# haltium_isimcore register map
Vendor: Nordic Semiconductor; Series: nRFHaltium; File version: 1
CPU: CM33 r0p4, little endian, MPU, FPU, 3 interrupt priority bits, 480 interrupts
Registers are 32-bit, read-write, reset 0x0 unless marked. A register's access mark holds for its fields unless they carry their own. Offsets are from the block's base; [hi:lo] are bit positions; lines under a group give offsets from that group; {n}, {i} and the like mark numbered series.

## GLOBAL_GGENERIC59_NS — GENERIC 0
Base 0xBF001000
Same registers: GENERIC0_NS 0x47002000, GENERIC6_NS 0x47021000, GENERIC7_NS 0x47022000, GENERIC8_NS 0x47023000, GENERIC9_NS 0x47024000, GLOBAL_GGENERIC55_NS 0x4F8D3000, GLOBAL_GGENERIC56_NS 0x4F8D4000, GLOBAL_GGENERIC57_NS 0x4F8D5000, GLOBAL_GGENERIC58_NS 0x4F8D6000, GENERIC2_NS 0x57004000, GENERIC4_NS 0x57014000, GENERIC5_NS 0x57015000, GLOBAL_GGENERIC55_S 0x5F8D3000, GLOBAL_GGENERIC56_S 0x5F8D4000, GLOBAL_GGENERIC57_S 0x5F8D5000, GLOBAL_GGENERIC58_S 0x5F8D6000, GLOBAL_GGENERIC59_S 0xBF001000 (alternate view of GLOBAL_GGENERIC59_NS), GLOBAL_GGENERIC60_NS 0xBF003000, GLOBAL_GGENERIC60_S 0xBF003000 (alternate view of GLOBAL_GGENERIC60_NS), GLOBAL_TSGEN_NS 0xBF041000, GLOBAL_ETB_NS 0xBF044000, GLOBAL_ETR_NS 0xBF045000
0x00 TASKS_GENERICTASK wo — Generic event
  [0] TASKS_GENERICTASK
    1=Trigger task
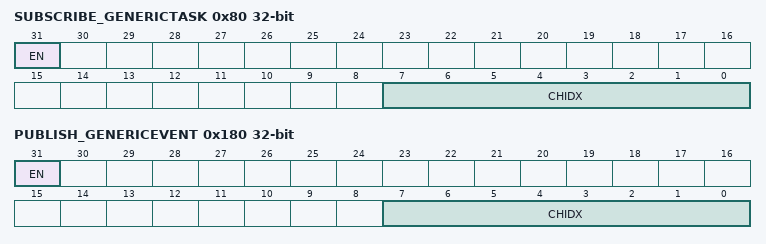
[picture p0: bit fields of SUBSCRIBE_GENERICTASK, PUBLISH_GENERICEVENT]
0x80 SUBSCRIBE_GENERICTASK — Subscribe configuration for task GENERICTASK
  [31] EN
    0=Disabled (Disable subscription); 1=Enabled (Enable subscription)
  [7:0] CHIDX — DPPI channel that task GENERICTASK will subscribe to
0x100 EVENTS_GENERICEVENT — Generic event
  [0] EVENTS_GENERICEVENT
    0=NotGenerated (Event not generated); 1=Generated (Event generated)
0x180 PUBLISH_GENERICEVENT — Publish configuration for event GENERICEVENT
  [31] EN
    0=Disabled (Disable publishing); 1=Enabled (Enable publishing)
  [7:0] CHIDX — DPPI channel that event GENERICEVENT will publish to
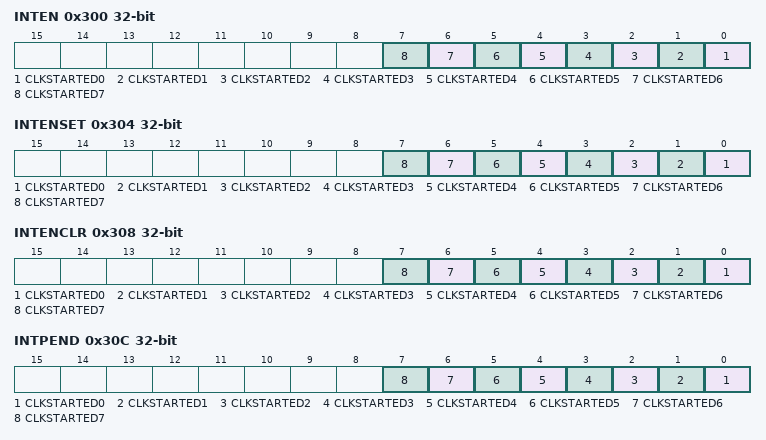
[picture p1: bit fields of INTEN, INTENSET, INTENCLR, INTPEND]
0x300 INTEN — Enable or disable interrupt
  [0] GENERICEVENT — Enable or disable interrupt for event GENERICEVENT
    0=Disabled; 1=Enabled
0x304 INTENSET — Enable interrupt
  [0] GENERICEVENT — Write '1' to enable interrupt for event GENERICEVENT
    on read: 0=Disabled (Read: Disabled); 1=Enabled (Read: Enabled) | on write: 1=Set (Enable)
0x308 INTENCLR — Disable interrupt
  [0] GENERICEVENT — Write '1' to disable interrupt for event GENERICEVENT
    on read: 0=Disabled (Read: Disabled); 1=Enabled (Read: Enabled) | on write: 1=Clear (Disable)

## CPUCONF_NS — CPU Configuration 0
Base 0x47001000
Same registers: CPUCONF_S 0x57001000
0x00 TASKS_ERASECACHE wo — Erase the caches used by the CPU.
  [0] TASKS_ERASECACHE
    1=Trigger task
0x500 INITSVTOR — Initial value of the secure VTOR (Vector Table Offset Register) after CPU reset.
  [31:0] INITSVTOR — Initial value of the VTOR.
0x504 INITNSVTOR — Initial value of the non-secure VTOR (Vector Table Offset Register).
  [31:0] INITNSVTOR — Initial value of the VTOR.
0x508 CPUSTART — Enable for starting the CPU
  [0] EN — Enable to start the CPU.
    0=Stopped (CPU stopped.); 1=Started (CPU started.)
0x50C CPUWAIT — Enable for the CPU wait.
  [0] EN — Enable to the CPU wait.
    0=Disabled (CPU is not waiting.); 1=Enabled (CPU is waiting.)

## LRC0_NS — LRC 0
Base 0x57003000
Same registers: LRC1_NS 0x57013000
{0x0+4i} TASKS_CLKSTART[{i}] (i=0..7) wo — Description collection: Start the clock source [n]
  [0] TASKS_CLKSTART — Start the clock source [n]
    1=Trigger task
{0x20+4i} TASKS_CLKSTOP[{i}] (i=0..7) wo — Description collection: Clear the TASKS_CLKSTART[n] request
  [0] TASKS_CLKSTOP — Clear the TASKS_CLKSTART[n] request
    1=Trigger task
0x40 TASKS_CONSTLAT wo — Enable constant latency mode
  [0] TASKS_CONSTLAT
    1=Trigger task
0x44 TASKS_LOWPWR wo — Enable Low Power mode
  [0] TASKS_LOWPWR
    1=Trigger task
{0x100+4i} EVENTS_CLKSTARTED[{i}] (i=0..7) — Description collection: Clock [n] started
  [0] EVENTS_CLKSTARTED — Clock [n] started
    0=NotGenerated (Event not generated); 1=Generated (Event generated)
0x300 INTEN — Enable or disable interrupt
  [all] fields
    0=Disabled; 1=Enabled
  [n] CLKSTARTED{n} (n=0..7) — Enable or disable interrupt for event CLKSTARTED[{n}]
0x304 INTENSET — Enable interrupt
  [all] fields
    on read: 0=Disabled (Read: Disabled); 1=Enabled (Read: Enabled) | on write: 1=Set (Enable)
  [n] CLKSTARTED{n} (n=0..7) — Write '1' to enable interrupt for event CLKSTARTED[{n}]
0x308 INTENCLR — Disable interrupt
  [all] fields
    on read: 0=Disabled (Read: Disabled); 1=Enabled (Read: Enabled) | on write: 1=Clear (Disable)
  [n] CLKSTARTED{n} (n=0..7) — Write '1' to disable interrupt for event CLKSTARTED[{n}]
0x30C INTPEND ro — Pending interrupts
  [all] fields
    on read: 0=NotPending (Read: Not pending); 1=Pending (Read: Pending)
  [n] CLKSTARTED{n} (n=0..7) — Read pending status of interrupt for event CLKSTARTED[{n}]
{0x400+8i} CLKSTAT[{i}] (i=0..7) group — Unspecified
  0x00 RUN — Description cluster: Status indicating that TASKS_START task has been triggered for clock [n]
    [0] STATUS — Clock start task triggered or not
      0=NotTriggered (Task not triggered); 1=Triggered (Task triggered)
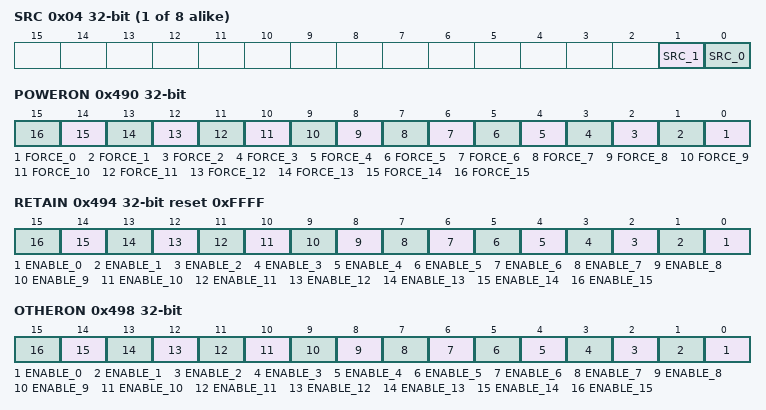
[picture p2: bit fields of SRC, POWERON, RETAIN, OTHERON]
  0x04 SRC — Description cluster: Status indicating which clock source is running for clock [n]
    [1] SRC_1 — Clock source
    [0] SRC_0 — Clock source
{0x440+8i} CLKCTRL[{i}] (i=0..7) group — Unspecified
  0x00 ALWAYSRUN — Description cluster: Force the clock source [n] and tree running always
    [0] FORCE — Force the clock always running
      0=Automatic clock control enabled; 1=AlwaysRun (Clock always running)
  0x04 SRC — Description cluster: Select the clock source for clock [n]
    [1] SRC_1 — Clock source
    [0] SRC_0 — Clock source
0x480 CONSTLATSTAT — Status of constant latency
  [0] STATUS
    0=Low power enabled; 1=ConstLat (Constant latency enabled)
0x490 POWERON — Force power domain ON
  [all] fields
    0=Automatic power control enabled; 1=AlwaysOn (Keep the power domain ON to the domain even though there is no request)
  [n] FORCE_{n} (n=0..15) — Force the power domain ON for domain[{n}]
0x494 RETAIN reset 0xFFFF — Retain power domain
  [all] fields
    0=Disable (Retain disabled); 1=Enable (retain enabled)
  [n] ENABLE_{n} (n=0..15) — Retain the power domain on for domain[{n}]
0x498 OTHERON — Request other domain ON
  [all] fields
    0=Automatic power control enabled; 1=AlwaysOn (Request to keep the other power domain ON to the domain even though there is no request)
  [n] ENABLE_{n} (n=0..15) — Request power domain ON for other domain[{n}]

## Notices in the file
Copyright (c) 2010 - 2020, Nordic Semiconductor ASA
All rights reserved.
Redistribution and use in source and binary forms, with or without modification,
are permitted provided that the following conditions are met:
1. Redistributions of source code must retain the above copyright notice, this
list of conditions and the following disclaimer.
2. Redistributions in binary form, except as embedded into a Nordic
Semiconductor ASA integrated circuit in a product or a software update for
such product, must reproduce the above copyright notice, this list of
conditions and the following disclaimer in the documentation and/or other
materials provided with the distribution.
3. Neither the name of Nordic Semiconductor ASA nor the names of its
contributors may be used to endorse or promote products derived from this
software without specific prior written permission.
4. This software, with or without modification, must only be used with a
Nordic Semiconductor ASA integrated circuit.
5. Any software provided in binary form under this license must not be reverse
engineered, decompiled, modified and/or disassembled.
THIS SOFTWARE IS PROVIDED BY NORDIC SEMICONDUCTOR ASA "AS IS" AND ANY EXPRESS
OR IMPLIED WARRANTIES, INCLUDING, BUT NOT LIMITED TO, THE IMPLIED WARRANTIES
OF MERCHANTABILITY, NONINFRINGEMENT, AND FITNESS FOR A PARTICULAR PURPOSE ARE
DISCLAIMED. IN NO EVENT SHALL NORDIC SEMICONDUCTOR ASA OR CONTRIBUTORS BE
LIABLE FOR ANY DIRECT, INDIRECT, INCIDENTAL, SPECIAL, EXEMPLARY, OR
CONSEQUENTIAL DAMAGES (INCLUDING, BUT NOT LIMITED TO, PROCUREMENT OF SUBSTITUTE
GOODS OR SERVICES; LOSS OF USE, DATA, OR PROFITS; OR BUSINESS INTERRUPTION)
HOWEVER CAUSED AND ON ANY THEORY OF LIABILITY, WHETHER IN CONTRACT, STRICT
LIABILITY, OR TORT (INCLUDING NEGLIGENCE OR OTHERWISE) ARISING IN ANY WAY OUT
OF THE USE OF THIS SOFTWARE, EVEN IF ADVISED OF THE POSSIBILITY OF SUCH DAMAGE.
